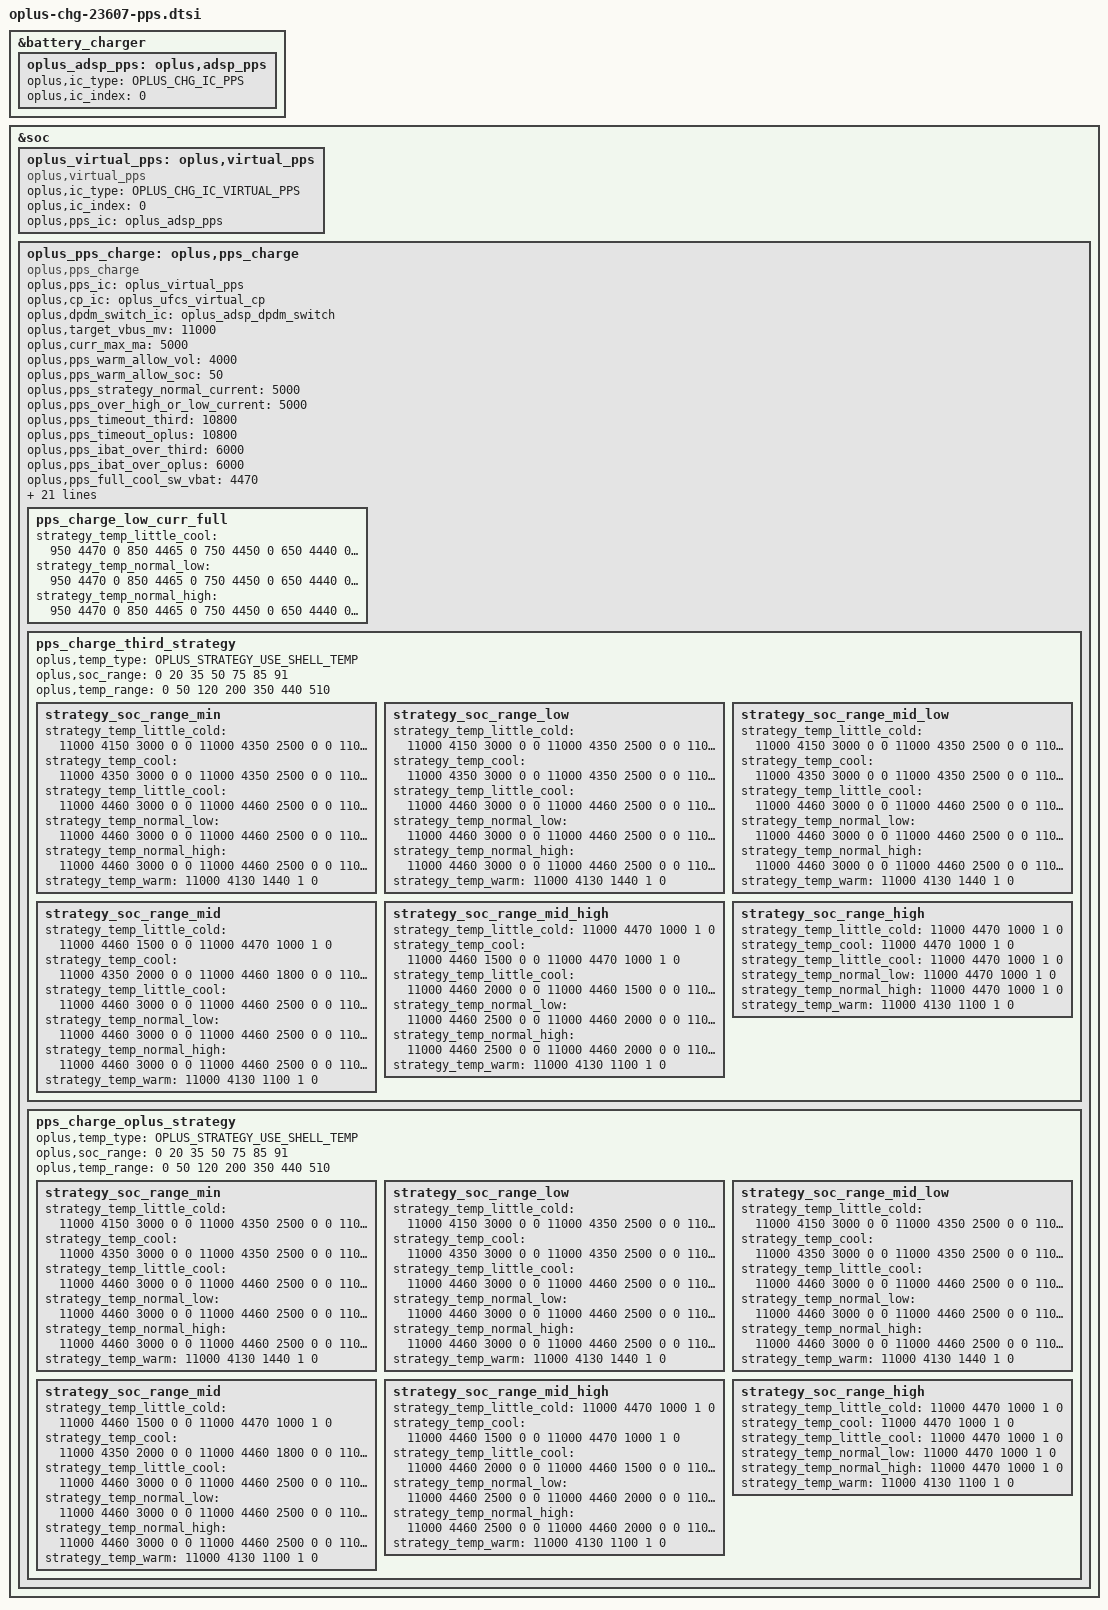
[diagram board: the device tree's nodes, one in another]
//ifdef OPLUS_FEATURE_CHG_BASIC

&battery_charger {
	oplus_adsp_pps: oplus,adsp_pps {
		oplus,ic_type = <OPLUS_CHG_IC_PPS>;
		oplus,ic_index = <0>;
	};
};
&soc {
	oplus_virtual_pps: oplus,virtual_pps {
		compatible = "oplus,virtual_pps";

		oplus,ic_type = <OPLUS_CHG_IC_VIRTUAL_PPS>;
		oplus,ic_index = <0>;
		oplus,pps_ic = <&oplus_adsp_pps>;
	};
	oplus_pps_charge: oplus,pps_charge {
		compatible = "oplus,pps_charge";
		oplus,pps_ic = <&oplus_virtual_pps>;
		oplus,cp_ic = <&oplus_ufcs_virtual_cp>;
		oplus,dpdm_switch_ic = <&oplus_adsp_dpdm_switch>;

		// oplus,impedance_unit = <&oplus_pps_impedance_unit>;

		oplus,target_vbus_mv = <11000>;
		oplus,curr_max_ma = <5000>;

		oplus,pps_warm_allow_vol = <4000>;
		oplus,pps_warm_allow_soc = <50>;
		oplus,pps_strategy_normal_current = <5000>;
		oplus,pps_over_high_or_low_current = <5000>;
		oplus,pps_timeout_third = <10800>;
		oplus,pps_timeout_oplus = <10800>;
		oplus,pps_ibat_over_third = <6000>;
		oplus,pps_ibat_over_oplus = <6000>;
		oplus,pps_full_cool_sw_vbat = <4470>;
		oplus,pps_full_normal_sw_vbat = <4470>;
		oplus,pps_full_normal_hw_vbat = <4480>;
		oplus,pps_full_ffc_vbat = <4520>;
		oplus,pps_full_warm_vbat = <4130>;
		oplus,pps_full_cool_sw_vbat_third = <4470>;
		oplus,pps_full_normal_sw_vbat_third= <4470>;
		oplus,pps_full_normal_hw_vbat_third = <4480>;
		oplus,pps_current_change_timeout = <100>;
		oplus,pps_r_default = <270 45 10 45 20 20 20>;
		oplus,pps_rmos_mohm = <5>;
		oplus,pps_r_limit = <150 100 80 70 30>;
		oplus,pps_strategy_batt_high_temp = <410 420 430 400 410 420>;
		oplus,pps_strategy_high_current = <5000 4000 4000 5000 5000 5000>;
		oplus,pps_charge_strategy_soc = <0 20 35 50 75 85 90>;
		oplus,pps_charge_strategy_temp = <0 50 120 200 350 440 510>;
		oplus,pps_low_curr_full_strategy_temp = <0 200 350 440>;

		pps_charge_low_curr_full {
			strategy_temp_little_cool = 	<950 4470 0
							 850 4465 0
							 750 4450 0
							 650 4440 0
							 550 4430 1>;
			strategy_temp_normal_low =	<950 4470 0
							 850 4465 0
							 750 4450 0
							 650 4440 0
							 550 4430 1>;
			strategy_temp_normal_high = 	<950 4470 0
							 850 4465 0
							 750 4450 0
							 650 4440 0
							 550 4430 1>;
		};

		pps_charge_third_strategy {
			oplus,temp_type = <OPLUS_STRATEGY_USE_SHELL_TEMP>;
			oplus,soc_range = <0 20 35 50 75 85 91>;
			oplus,temp_range = <0 50 120 200 350 440 510>;

			strategy_soc_range_min {
				strategy_temp_little_cold =	<11000 4150 3000 0 0
								11000 4350 2500 0 0
								11000 4350 2000 0 0
								11000 4460 1800 0 0
								11000 4460 1500 0 0
								11000 4470 1000 1 0>;
				strategy_temp_cool =		<11000 4350 3000 0 0
								11000 4350 2500 0 0
								11000 4350 2000 0 0
								11000 4460 1800 0 0
								11000 4460 1500 0 0
								11000 4470 1000 1 0>;
				strategy_temp_little_cool =	<11000 4460 3000 0 0
								11000 4460 2500 0 0
								11000 4460 2000 0 0
								11000 4460 1500 0 0
								11000 4470 1000 1 0>;
				strategy_temp_normal_low =	<11000 4460 3000 0 0
								11000 4460 2500 0 0
								11000 4460 2000 0 0
								11000 4460 1500 0 0
								11000 4460 1400 0 0
								11000 4470 1000 1 0>;
				strategy_temp_normal_high =	<11000 4460 3000 0 0
								11000 4460 2500 0 0
								11000 4460 2000 0 0
								11000 4460 1600 0 0
								11000 4470 1000 1 0>;
				strategy_temp_warm =		<11000 4130 1440 1 0>;
			};
			strategy_soc_range_low {
				strategy_temp_little_cold =	<11000 4150 3000 0 0
								11000 4350 2500 0 0
								11000 4350 2000 0 0
								11000 4460 1800 0 0
								11000 4460 1500 0 0
								11000 4470 1000 1 0>;
				strategy_temp_cool =		<11000 4350 3000 0 0
								11000 4350 2500 0 0
								11000 4350 2000 0 0
								11000 4460 1800 0 0
								11000 4460 1500 0 0
								11000 4470 1000 1 0>;
				strategy_temp_little_cool =	<11000 4460 3000 0 0
								11000 4460 2500 0 0
								11000 4460 2000 0 0
								11000 4460 1500 0 0
								11000 4470 1000 1 0>;
				strategy_temp_normal_low =	<11000 4460 3000 0 0
								11000 4460 2500 0 0
								11000 4460 2000 0 0
								11000 4460 1500 0 0
								11000 4460 1400 0 0
								11000 4470 1000 1 0>;
				strategy_temp_normal_high =	<11000 4460 3000 0 0
								11000 4460 2500 0 0
								11000 4460 2000 0 0
								11000 4460 1600 0 0
								11000 4470 1000 1 0>;
				strategy_temp_warm =		<11000 4130 1440 1 0>;
			};
			strategy_soc_range_mid_low {
				strategy_temp_little_cold =	<11000 4150 3000 0 0
								11000 4350 2500 0 0
								11000 4350 2000 0 0
								11000 4460 1800 0 0
								11000 4460 1500 0 0
								11000 4470 1000 1 0>;
				strategy_temp_cool =		<11000 4350 3000 0 0
								11000 4350 2500 0 0
								11000 4350 2000 0 0
								11000 4460 1800 0 0
								11000 4460 1500 0 0
								11000 4470 1000 1 0>;
				strategy_temp_little_cool =	<11000 4460 3000 0 0
								11000 4460 2500 0 0
								11000 4460 2000 0 0
								11000 4460 1500 0 0
								11000 4470 1000 1 0>;
				strategy_temp_normal_low =	<11000 4460 3000 0 0
								11000 4460 2500 0 0
								11000 4460 2000 0 0
								11000 4460 1500 0 0
								11000 4460 1400 0 0
								11000 4470 1000 1 0>;
				strategy_temp_normal_high =	<11000 4460 3000 0 0
								11000 4460 2500 0 0
								11000 4460 2000 0 0
								11000 4460 1600 0 0
								11000 4470 1000 1 0>;
				strategy_temp_warm =		<11000 4130 1440 1 0>;
			};
			strategy_soc_range_mid {
				strategy_temp_little_cold =	<11000 4460 1500 0 0
								11000 4470 1000 1 0>;
				strategy_temp_cool =		<11000 4350 2000 0 0
								11000 4460 1800 0 0
								11000 4460 1500 0 0
								11000 4470 1000 1 0>;
				strategy_temp_little_cool =	<11000 4460 3000 0 0
								11000 4460 2500 0 0
								11000 4460 2000 0 0
								11000 4460 1500 0 0
								11000 4470 1000 1 0>;
				strategy_temp_normal_low =	<11000 4460 3000 0 0
								11000 4460 2500 0 0
								11000 4460 2000 0 0
								11000 4460 1500 0 0
								11000 4460 1400 0 0
								11000 4470 1000 1 0>;
				strategy_temp_normal_high =	<11000 4460 3000 0 0
								11000 4460 2500 0 0
								11000 4460 2000 0 0
								11000 4460 1600 0 0
								11000 4470 1000 1 0>;
				strategy_temp_warm =		<11000 4130 1100 1 0>;
			};
			strategy_soc_range_mid_high {
				strategy_temp_little_cold =	<11000 4470 1000 1 0>;
				strategy_temp_cool =		<11000 4460 1500 0 0
								11000 4470 1000 1 0>;
				strategy_temp_little_cool =	<11000 4460 2000 0 0
								11000 4460 1500 0 0
								11000 4470 1000 1 0>;
				strategy_temp_normal_low =	<11000 4460 2500 0 0
								11000 4460 2000 0 0
								11000 4460 1500 0 0
								11000 4460 1400 0 0
								11000 4470 1000 1 0>;
				strategy_temp_normal_high =	<11000 4460 2500 0 0
								11000 4460 2000 0 0
								11000 4460 1600 0 0
								11000 4470 1000 1 0>;
				strategy_temp_warm =		<11000 4130 1100 1 0>;
			};
			strategy_soc_range_high {
				strategy_temp_little_cold =	<11000 4470 1000 1 0>;
				strategy_temp_cool =		<11000 4470 1000 1 0>;
				strategy_temp_little_cool =	<11000 4470 1000 1 0>;
				strategy_temp_normal_low =	<11000 4470 1000 1 0>;
				strategy_temp_normal_high =	<11000 4470 1000 1 0>;
				strategy_temp_warm =		<11000 4130 1100 1 0>;
			};
		};

		pps_charge_oplus_strategy {
			oplus,temp_type = <OPLUS_STRATEGY_USE_SHELL_TEMP>;
			oplus,soc_range = <0 20 35 50 75 85 91>;
			oplus,temp_range = <0 50 120 200 350 440 510>;

			strategy_soc_range_min {
				strategy_temp_little_cold =	<11000 4150 3000 0 0
								11000 4350 2500 0 0
								11000 4350 2000 0 0
								11000 4460 1800 0 0
								11000 4460 1500 0 0
								11000 4470 1000 1 0>;
				strategy_temp_cool =		<11000 4350 3000 0 0
								11000 4350 2500 0 0
								11000 4350 2000 0 0
								11000 4460 1800 0 0
								11000 4460 1500 0 0
								11000 4470 1000 1 0>;
				strategy_temp_little_cool =	<11000 4460 3000 0 0
								11000 4460 2500 0 0
								11000 4460 2000 0 0
								11000 4460 1500 0 0
								11000 4470 1000 1 0>;
				strategy_temp_normal_low =	<11000 4460 3000 0 0
								11000 4460 2500 0 0
								11000 4460 2000 0 0
								11000 4460 1500 0 0
								11000 4460 1400 0 0
								11000 4470 1000 1 0>;
				strategy_temp_normal_high =	<11000 4460 3000 0 0
								11000 4460 2500 0 0
								11000 4460 2000 0 0
								11000 4460 1600 0 0
								11000 4470 1000 1 0>;
				strategy_temp_warm =		<11000 4130 1440 1 0>;
			};
			strategy_soc_range_low {
				strategy_temp_little_cold =	<11000 4150 3000 0 0
								11000 4350 2500 0 0
								11000 4350 2000 0 0
								11000 4460 1800 0 0
								11000 4460 1500 0 0
								11000 4470 1000 1 0>;
				strategy_temp_cool =		<11000 4350 3000 0 0
								11000 4350 2500 0 0
								11000 4350 2000 0 0
								11000 4460 1800 0 0
								11000 4460 1500 0 0
								11000 4470 1000 1 0>;
				strategy_temp_little_cool =	<11000 4460 3000 0 0
								11000 4460 2500 0 0
								11000 4460 2000 0 0
								11000 4460 1500 0 0
								11000 4470 1000 1 0>;
				strategy_temp_normal_low =	<11000 4460 3000 0 0
								11000 4460 2500 0 0
								11000 4460 2000 0 0
								11000 4460 1500 0 0
								11000 4460 1400 0 0
								11000 4470 1000 1 0>;
				strategy_temp_normal_high =	<11000 4460 3000 0 0
								11000 4460 2500 0 0
								11000 4460 2000 0 0
								11000 4460 1600 0 0
								11000 4470 1000 1 0>;
				strategy_temp_warm =		<11000 4130 1440 1 0>;
			};
			strategy_soc_range_mid_low {
				strategy_temp_little_cold =	<11000 4150 3000 0 0
								11000 4350 2500 0 0
								11000 4350 2000 0 0
								11000 4460 1800 0 0
								11000 4460 1500 0 0
								11000 4470 1000 1 0>;
				strategy_temp_cool =		<11000 4350 3000 0 0
								11000 4350 2500 0 0
								11000 4350 2000 0 0
								11000 4460 1800 0 0
								11000 4460 1500 0 0
								11000 4470 1000 1 0>;
				strategy_temp_little_cool =	<11000 4460 3000 0 0
								11000 4460 2500 0 0
								11000 4460 2000 0 0
								11000 4460 1500 0 0
								11000 4470 1000 1 0>;
				strategy_temp_normal_low =	<11000 4460 3000 0 0
								11000 4460 2500 0 0
								11000 4460 2000 0 0
								11000 4460 1500 0 0
								11000 4460 1400 0 0
								11000 4470 1000 1 0>;
				strategy_temp_normal_high =	<11000 4460 3000 0 0
								11000 4460 2500 0 0
								11000 4460 2000 0 0
								11000 4460 1600 0 0
								11000 4470 1000 1 0>;
				strategy_temp_warm =		<11000 4130 1440 1 0>;
			};
			strategy_soc_range_mid {
				strategy_temp_little_cold =	<11000 4460 1500 0 0
								11000 4470 1000 1 0>;
				strategy_temp_cool =		<11000 4350 2000 0 0
								11000 4460 1800 0 0
								11000 4460 1500 0 0
								11000 4470 1000 1 0>;
				strategy_temp_little_cool =	<11000 4460 3000 0 0
								11000 4460 2500 0 0
								11000 4460 2000 0 0
								11000 4460 1500 0 0
								11000 4470 1000 1 0>;
				strategy_temp_normal_low =	<11000 4460 3000 0 0
								11000 4460 2500 0 0
								11000 4460 2000 0 0
								11000 4460 1500 0 0
								11000 4460 1400 0 0
								11000 4470 1000 1 0>;
				strategy_temp_normal_high =	<11000 4460 3000 0 0
								11000 4460 2500 0 0
								11000 4460 2000 0 0
								11000 4460 1600 0 0
								11000 4470 1000 1 0>;
				strategy_temp_warm =		<11000 4130 1100 1 0>;
			};
			strategy_soc_range_mid_high {
				strategy_temp_little_cold =	<11000 4470 1000 1 0>;
				strategy_temp_cool =		<11000 4460 1500 0 0
								11000 4470 1000 1 0>;
				strategy_temp_little_cool =	<11000 4460 2000 0 0
								11000 4460 1500 0 0
								11000 4470 1000 1 0>;
				strategy_temp_normal_low =	<11000 4460 2500 0 0
								11000 4460 2000 0 0
								11000 4460 1500 0 0
								11000 4460 1400 0 0
								11000 4470 1000 1 0>;
				strategy_temp_normal_high =	<11000 4460 2500 0 0
								11000 4460 2000 0 0
								11000 4460 1600 0 0
								11000 4470 1000 1 0>;
				strategy_temp_warm =		<11000 4130 1100 1 0>;
			};
			strategy_soc_range_high {
				strategy_temp_little_cold =	<11000 4470 1000 1 0>;
				strategy_temp_cool =		<11000 4470 1000 1 0>;
				strategy_temp_little_cool =	<11000 4470 1000 1 0>;
				strategy_temp_normal_low =	<11000 4470 1000 1 0>;
				strategy_temp_normal_high =	<11000 4470 1000 1 0>;
				strategy_temp_warm =		<11000 4130 1100 1 0>;
			};
		};
	};
};
//#endif OPLUS_FEATURE_CHG_BASIC
